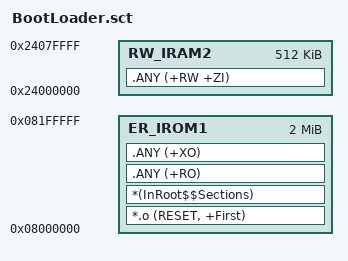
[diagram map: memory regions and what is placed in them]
; *************************************************************
; *** Scatter-Loading Description File generated by uVision ***
; *************************************************************
LR_IROM1 0x08000000 0x00200000 { 		; load region size_region
	ER_IROM1 0x08000000 0x00200000 { 	; load address = execution address
		*.o (RESET, +First)
		*(InRoot$$Sections)
		.ANY (+RO)
		.ANY (+XO)
	}
	
	; RW data - 512KB AXI SRAM
	RW_IRAM2 0x24000000 0x00080000 {
		.ANY (+RW +ZI)
	}
}

;Example: attribute((section (".RAM_D1")))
